AUTOSAR XML (schema 4-2-1)
package /RootP_ASWC_M414
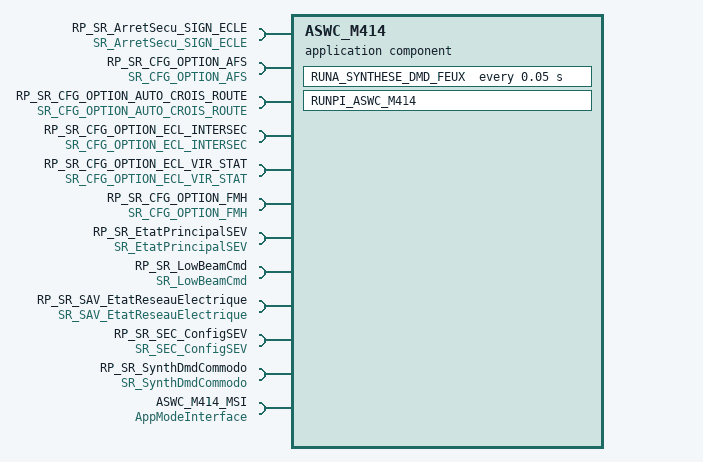
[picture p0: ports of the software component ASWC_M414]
  application sw component type ASWC_M414
    9 x provide/require port:
      PRP_SR_AFSFunctionAvailability: nonqueued-receiver-com-spec{data-element=AFSFunctionAvailability, enable-update=0, handle-data-status=1, handle-never-received=0, init-value=CONST_tLOG_0:0}, provided-required-interface=SR_AFSFunctionAvailability
      PRP_SR_AUTOLightingEngineOff: nonqueued-receiver-com-spec{data-element=AUTOLightingEngineOff, enable-update=0, handle-data-status=1, handle-never-received=0, init-value=CONST_tLOG_0:0}, provided-required-interface=SR_AUTOLightingEngineOff
      PRP_SR_CorneringLightAvailability: nonqueued-receiver-com-spec{data-element=CorneringLightAvailability, enable-update=0, handle-data-status=1, handle-never-received=0, init-value=CONST_tLOG_0:0}, provided-required-interface=SR_CorneringLightAvailability
      PRP_SR_FMHFctAvailability: nonqueued-receiver-com-spec{data-element=FMHFctAvailability, enable-update=0, handle-data-status=1, handle-never-received=0, init-value=CONST_tLOG_0:0}, provided-required-interface=SR_FMHFctAvailability
      PRP_SR_HighBeamAssistAvailability: nonqueued-receiver-com-spec{data-element=HighBeamAssistAvailability, enable-update=0, handle-data-status=1, handle-never-received=0, init-value=CONST_tLOG_0:0}, provided-required-interface=SR_HighBeamAssistAvailability
      PRP_SR_HighBeamAvailability: nonqueued-receiver-com-spec{data-element=HighBeamAvailability, enable-update=0, handle-data-status=1, handle-never-received=0, init-value=CONST_tLOG_0:0}, provided-required-interface=SR_HighBeamAvailability
      PRP_SR_LowBeamAvailability: nonqueued-receiver-com-spec{data-element=LowBeamAvailability, enable-update=0, handle-data-status=1, handle-never-received=0, init-value=CONST_tLOG_0:0}, provided-required-interface=SR_LowBeamAvailability
      PRP_SR_StatBendingAvailability: nonqueued-receiver-com-spec{data-element=StatBendingAvailability, enable-update=0, handle-data-status=1, handle-never-received=0, init-value=CONST_tLOG_0:0}, provided-required-interface=SR_StatBendingAvailability
      PRP_SR_SummarizeDmd: provided-required-interface=SR_SummarizeDmd
        required-com-specs:
          data-element=SummarizeDmd_DRL, enable-update=0, handle-data-status=1, handle-never-received=0, init-value=CONST_tLOG_0:0
          data-element=SummarizeDmd_Position, enable-update=0, handle-data-status=1, handle-never-received=0, init-value=CONST_tLOG_0:0
    12 x require port:
      RP_SR_ArretSecu_SIGN_ECLE: nonqueued-receiver-com-spec{data-element=ArretSecu_SIGN_ECLE, enable-update=0, handle-data-status=1, handle-never-received=0, init-value=CONST_tLOG_1:1}, required-interface=SR_ArretSecu_SIGN_ECLE
      RP_SR_CFG_OPTION_AFS: nonqueued-receiver-com-spec{data-element=CFG_OPTION_AFS, enable-update=0, handle-data-status=1, handle-never-received=0, init-value=CONST_tLOG_0:0}, required-interface=SR_CFG_OPTION_AFS
      RP_SR_CFG_OPTION_AUTO_CROIS_ROUTE: nonqueued-receiver-com-spec{data-element=CFG_OPTION_AUTO_CROIS_ROUTE, enable-update=0, handle-data-status=1, handle-never-received=0, init-value=CONST_tBILOG_0:0}, required-interface=SR_CFG_OPTION_AUTO_CROIS_ROUTE
      RP_SR_CFG_OPTION_ECL_INTERSEC: nonqueued-receiver-com-spec{data-element=CFG_OPTION_ECL_INTERSEC, enable-update=0, handle-data-status=1, handle-never-received=0, init-value=CONST_tLOG_0:0}, required-interface=SR_CFG_OPTION_ECL_INTERSEC
      RP_SR_CFG_OPTION_ECL_VIR_STAT: nonqueued-receiver-com-spec{data-element=CFG_OPTION_ECL_VIR_STAT, enable-update=0, handle-data-status=1, handle-never-received=0, init-value=CONST_tBILOG_0:0}, required-interface=SR_CFG_OPTION_ECL_VIR_STAT
      RP_SR_CFG_OPTION_FMH: nonqueued-receiver-com-spec{data-element=CFG_OPTION_FMH, enable-update=0, handle-data-status=1, handle-never-received=0, init-value=CONST_tLOG_0:0}, required-interface=SR_CFG_OPTION_FMH
      RP_SR_EtatPrincipalSEV: nonqueued-receiver-com-spec{data-element=EtatPrincipalSEV, enable-update=0, handle-data-status=1, handle-never-received=0, init-value=CONST_EtatPrincipalSEV_t_SEV_SEV_Arret:105}, required-interface=SR_EtatPrincipalSEV
      RP_SR_LowBeamCmd: nonqueued-receiver-com-spec{data-element=LowBeamCmd, enable-update=0, handle-data-status=1, handle-never-received=0, init-value=CONST_tLOG_0:0}, required-interface=SR_LowBeamCmd
      RP_SR_SAV_EtatReseauElectrique: nonqueued-receiver-com-spec{data-element=SAV_EtatReseauElectrique, enable-update=0, handle-data-status=1, handle-never-received=0, init-value=CONST_t_cGEE_1_0:0}, required-interface=SR_SAV_EtatReseauElectrique
      RP_SR_SEC_ConfigSEV: nonqueued-receiver-com-spec{data-element=SEC_ConfigSEV, enable-update=0, handle-data-status=1, handle-never-received=0, init-value=CONST_t_cCSEV_4:4}, required-interface=SR_SEC_ConfigSEV
      RP_SR_SynthDmdCommodo: nonqueued-receiver-com-spec{data-element=SynthDmdCommodo, enable-update=0, handle-data-status=1, handle-never-received=0, init-value=CONST_tBYTE_0:0}, required-interface=SR_SynthDmdCommodo
      ASWC_M414_MSI: required-interface=AppModeInterface
    behavior IB_ASWC_M414: data-type-mapping=ApplicationModeMapping, handle-termination-and-restart=NO-SUPPORT
      timing event RUNA_SYNTHESE_DMD_FEUX_Cyclic: start-on-event=RUNA_SYNTHESE_DMD_FEUX, period=0.05
        disabled-mode:
          ASWC_M414_MSI.AppMode.APP_WAKEUP
          ASWC_M414_MSI.AppMode.APP_OFF
          ASWC_M414_MSI.AppMode.APP_SYNC_INIT
          ASWC_M414_MSI.AppMode.APP_CONFIG
      swc mode switch event RUNPI_ASWC_M414_ENTRY: start-on-event=RUNPI_ASWC_M414, activation=ON-ENTRY, mode=ASWC_M414_MSI.AppMode.APP_WAKEUP
      runnable RUNA_SYNTHESE_DMD_FEUX
        data-read-access:
          21 x access:
            dra_RP_SR_ArretSecu_SIGN_ECLE_ArretSecu_SIGN_ECLE: accessed-variable=RP_SR_ArretSecu_SIGN_ECLE.ArretSecu_SIGN_ECLE
            dra_RP_SR_EtatPrincipalSEV_EtatPrincipalSEV: accessed-variable=RP_SR_EtatPrincipalSEV.EtatPrincipalSEV
            dra_RP_SR_LowBeamCmd_LowBeamCmd: accessed-variable=RP_SR_LowBeamCmd.LowBeamCmd
            dra_RP_SR_SAV_EtatReseauElectrique_SAV_EtatReseauElectrique: accessed-variable=RP_SR_SAV_EtatReseauElectrique.SAV_EtatReseauElectrique
            dra_RP_SR_SEC_ConfigSEV_SEC_ConfigSEV: accessed-variable=RP_SR_SEC_ConfigSEV.SEC_ConfigSEV
            dra_RP_SR_SynthDmdCommodo_SynthDmdCommodo: accessed-variable=RP_SR_SynthDmdCommodo.SynthDmdCommodo
            dra_RP_SR_CFG_OPTION_AFS_CFG_OPTION_AFS: accessed-variable=RP_SR_CFG_OPTION_AFS.CFG_OPTION_AFS
            dra_RP_SR_CFG_OPTION_AUTO_CROIS_ROUTE_CFG_OPTION_AUTO_CROIS_ROUTE: accessed-variable=RP_SR_CFG_OPTION_AUTO_CROIS_ROUTE.CFG_OPTION_AUTO_CROIS_ROUTE
            dra_RP_SR_CFG_OPTION_ECL_INTERSEC_CFG_OPTION_ECL_INTERSEC: accessed-variable=RP_SR_CFG_OPTION_ECL_INTERSEC.CFG_OPTION_ECL_INTERSEC
            dra_RP_SR_CFG_OPTION_ECL_VIR_STAT_CFG_OPTION_ECL_VIR_STAT: accessed-variable=RP_SR_CFG_OPTION_ECL_VIR_STAT.CFG_OPTION_ECL_VIR_STAT
            dra_RP_SR_CFG_OPTION_FMH_CFG_OPTION_FMH: accessed-variable=RP_SR_CFG_OPTION_FMH.CFG_OPTION_FMH
            dra_PRP_SR_AFSFunctionAvailability_AFSFunctionAvailability: accessed-variable=PRP_SR_AFSFunctionAvailability.AFSFunctionAvailability
            dra_PRP_SR_AUTOLightingEngineOff_AUTOLightingEngineOff: accessed-variable=PRP_SR_AUTOLightingEngineOff.AUTOLightingEngineOff
            dra_PRP_SR_CorneringLightAvailability_CorneringLightAvailability: accessed-variable=PRP_SR_CorneringLightAvailability.CorneringLightAvailability
            dra_PRP_SR_FMHFctAvailability_FMHFctAvailability: accessed-variable=PRP_SR_FMHFctAvailability.FMHFctAvailability
            dra_PRP_SR_HighBeamAssistAvailability_HighBeamAssistAvailability: accessed-variable=PRP_SR_HighBeamAssistAvailability.HighBeamAssistAvailability
            dra_PRP_SR_HighBeamAvailability_HighBeamAvailability: accessed-variable=PRP_SR_HighBeamAvailability.HighBeamAvailability
            dra_PRP_SR_LowBeamAvailability_LowBeamAvailability: accessed-variable=PRP_SR_LowBeamAvailability.LowBeamAvailability
            dra_PRP_SR_StatBendingAvailability_StatBendingAvailability: accessed-variable=PRP_SR_StatBendingAvailability.StatBendingAvailability
            dra_PRP_SR_SummarizeDmd_SummarizeDmd_DRL: accessed-variable=PRP_SR_SummarizeDmd.SummarizeDmd_DRL
            dra_PRP_SR_SummarizeDmd_SummarizeDmd_Position: accessed-variable=PRP_SR_SummarizeDmd.SummarizeDmd_Position
        data-write-access:
          10 x access:
            dwa_PRP_SR_AFSFunctionAvailability_AFSFunctionAvailability: accessed-variable=PRP_SR_AFSFunctionAvailability.AFSFunctionAvailability
            dwa_PRP_SR_AUTOLightingEngineOff_AUTOLightingEngineOff: accessed-variable=PRP_SR_AUTOLightingEngineOff.AUTOLightingEngineOff
            dwa_PRP_SR_CorneringLightAvailability_CorneringLightAvailability: accessed-variable=PRP_SR_CorneringLightAvailability.CorneringLightAvailability
            dwa_PRP_SR_FMHFctAvailability_FMHFctAvailability: accessed-variable=PRP_SR_FMHFctAvailability.FMHFctAvailability
            dwa_PRP_SR_HighBeamAssistAvailability_HighBeamAssistAvailability: accessed-variable=PRP_SR_HighBeamAssistAvailability.HighBeamAssistAvailability
            dwa_PRP_SR_HighBeamAvailability_HighBeamAvailability: accessed-variable=PRP_SR_HighBeamAvailability.HighBeamAvailability
            dwa_PRP_SR_LowBeamAvailability_LowBeamAvailability: accessed-variable=PRP_SR_LowBeamAvailability.LowBeamAvailability
            dwa_PRP_SR_StatBendingAvailability_StatBendingAvailability: accessed-variable=PRP_SR_StatBendingAvailability.StatBendingAvailability
            dwa_PRP_SR_SummarizeDmd_SummarizeDmd_DRL: accessed-variable=PRP_SR_SummarizeDmd.SummarizeDmd_DRL
            dwa_PRP_SR_SummarizeDmd_SummarizeDmd_Position: accessed-variable=PRP_SR_SummarizeDmd.SummarizeDmd_Position
      runnable RUNPI_ASWC_M414
package /RootP_Implementatation
  swc implementation Implementatation_ASWC_M414: programming-language=C, sw-version=1.0.0, vendor-id=1, behavior=IB_ASWC_M414
    code-descriptors:
      code SRC: artifact-descriptors=autosar-engineering-object={short-label=EngObject, category=SWSRC}
    resource consumption Resources
